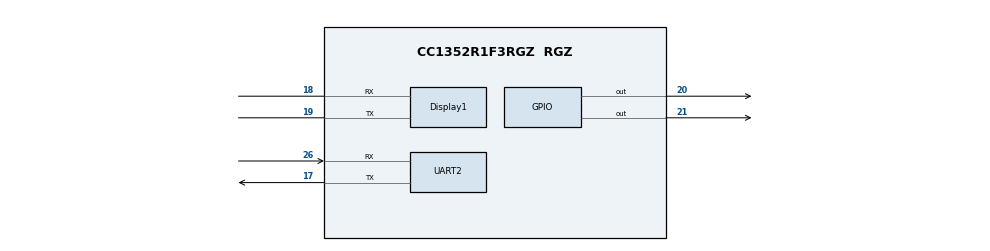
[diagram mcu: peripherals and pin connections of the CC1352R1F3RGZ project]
/**
 * These arguments were used when this file was generated. They will be automatically applied on subsequent loads
 * via the GUI or CLI. Run CLI with '--help' for additional information on how to override these arguments.
 * @cliArgs --device "CC1352R1F3RGZ" --package "RGZ" --part "Default" --product "simplelink_cc13x2_26x2_sdk@5.20.00.52"
 * @versions {"data":"2021060817","timestamp":"2021060817","tool":"1.8.2+1992","templates":null}
 */

/**
 * Import the modules used in this configuration.
 */
const ble         = scripting.addModule("/ti/ble5stack/ble");
const CCFG        = scripting.addModule("/ti/devices/CCFG");
const rfdesign    = scripting.addModule("/ti/devices/radioconfig/rfdesign");
const Display     = scripting.addModule("/ti/display/Display");
const Display1    = Display.addInstance();
const AESCCM      = scripting.addModule("/ti/drivers/AESCCM");
const AESCCM1     = AESCCM.addInstance();
const AESCTRDRBG  = scripting.addModule("/ti/drivers/AESCTRDRBG");
const AESCTRDRBG1 = AESCTRDRBG.addInstance();
const AESECB      = scripting.addModule("/ti/drivers/AESECB");
const AESECB1     = AESECB.addInstance();
const ECDH        = scripting.addModule("/ti/drivers/ECDH");
const ECDH1       = ECDH.addInstance();
const GPIO        = scripting.addModule("/ti/drivers/GPIO");
const GPIO1       = GPIO.addInstance();
const GPIO2       = GPIO.addInstance();
const NVS         = scripting.addModule("/ti/drivers/NVS");
const NVS1        = NVS.addInstance();
const Power       = scripting.addModule("/ti/drivers/Power");
const RF          = scripting.addModule("/ti/drivers/RF");
const RTOS        = scripting.addModule("/ti/drivers/RTOS");
const TRNG        = scripting.addModule("/ti/drivers/TRNG");
const TRNG1       = TRNG.addInstance();
const UART        = scripting.addModule("/ti/drivers/UART", {}, false);
const UART2       = UART.addInstance();

/**
 * Write custom configuration values to the imported modules.
 */
ble.deviceRole                                            = "PERIPHERAL_CFG+CENTRAL_CFG";
ble.disDevBySerUuid                                       = true;
ble.numOfAdvSets                                          = 1;
ble.numOfDefAdvSets                                       = 1;
ble.bondPairing                                           = "GAPBOND_PAIRING_MODE_NO_PAIRING";
ble.bondMITMProtection                                    = false;
ble.bonding                                               = false;
ble.radioConfig.codeExportConfig.$name                    = "ti_devices_radioconfig_code_export_param0";
ble.connUpdateParamsPeripheral.$name                      = "ti_ble5stack_general_ble_conn_update_params0";
ble.connUpdateParamsCentral.$name                         = "ti_ble5stack_general_ble_conn_update_params1";
ble.advSet1.$name                                         = "ti_ble5stack_broadcaster_advertisement_set0";
ble.advSet1.advParam1.$name                               = "ti_ble5stack_broadcaster_advertisement_params0";
ble.advSet1.advData1.$name                                = "ti_ble5stack_broadcaster_advertisement_data0";
ble.advSet1.advData1.GAP_ADTYPE_FLAGS                     = true;
ble.advSet1.advData1.advertisingFlags                     = ["GAP_ADTYPE_FLAGS_BREDR_NOT_SUPPORTED","GAP_ADTYPE_FLAGS_GENERAL"];
ble.advSet1.advData1.GAP_ADTYPE_16BIT_MORE                = true;
ble.advSet1.advData1.numOfUUIDs16More                     = 1;
ble.advSet1.advData1.UUID016More                          = 0xFFF0;
ble.advSet1.scanRes1.$name                                = "ti_ble5stack_broadcaster_advertisement_data1";
ble.advSet1.scanRes1.GAP_ADTYPE_LOCAL_NAME_COMPLETE       = true;
ble.advSet1.scanRes1.completeLocalName                    = "Multi Role";
ble.advSet1.scanRes1.GAP_ADTYPE_SLAVE_CONN_INTERVAL_RANGE = true;
ble.advSet1.scanRes1.maxConnInterval                      = 130;
ble.advSet1.scanRes1.GAP_ADTYPE_POWER_LEVEL               = true;

CCFG.enableBootloader         = true;
CCFG.enableBootloaderBackdoor = true;
CCFG.dioBootloaderBackdoor    = 15;
CCFG.levelBootloaderBackdoor  = "Active low";
CCFG.ccfgTemplate.$name       = "ti_devices_CCFGTemplate0";

rfdesign.fbSub1g = "none";

Display1.$name                          = "CONFIG_Display_0";
Display1.enableANSI                     = true;
Display1.uartBufferSize                 = 128;
Display1.uart.$name                     = "CONFIG_DISPLAY_UART";
Display1.uart.uart.$assign              = "UART1";
Display1.uart.uart.txPin.$assign        = "19";
Display1.uart.uart.rxPin.$assign        = "18";
Display1.uart.txPinInstance.outputState = "High";
Display1.uart.txPinInstance.$name       = "CONFIG_PIN_UART_TX";
Display1.uart.rxPinInstance.$name       = "CONFIG_PIN_UART_RX";

AESCCM1.$name = "CONFIG_AESCCM0";

AESCTRDRBG1.$name              = "CONFIG_AESCTRDRBG_0";
AESCTRDRBG1.aesctrObject.$name = "CONFIG_AESCTR_0";

AESECB1.$name = "CONFIG_AESECB0";

ECDH1.$name = "CONFIG_ECDH0";

GPIO1.pull              = "Pull Up";
GPIO1.interruptTrigger  = "Falling Edge";
GPIO1.mode              = "Dynamic";
GPIO1.$name             = "CONFIG_GPIO_BTN1";
GPIO1.gpioPin.$assign   = "21";
GPIO1.pinInstance.$name = "CONFIG_PIN_BTN1";

GPIO2.pull              = "Pull Up";
GPIO2.interruptTrigger  = "Falling Edge";
GPIO2.mode              = "Dynamic";
GPIO2.$name             = "CONFIG_GPIO_BTN2";
GPIO2.gpioPin.$assign   = "20";
GPIO2.pinInstance.$name = "CONFIG_PIN_BTN2";

NVS1.$name                    = "CONFIG_NVSINTERNAL";
NVS1.internalFlash.$name      = "ti_drivers_nvs_NVSCC26XX0";
NVS1.internalFlash.regionBase = 0x48000;
NVS1.internalFlash.regionSize = 0x4000;

TRNG1.$name = "CONFIG_TRNG_0";

UART2.$name               = "CONFIG_UART_0";
UART2.uart.$assign        = "UART0";
UART2.uart.txPin.$assign  = "17";
UART2.uart.rxPin.$assign  = "26";
UART2.txPinInstance.$name = "CONFIG_PIN_2";
UART2.rxPinInstance.$name = "CONFIG_PIN_3";
